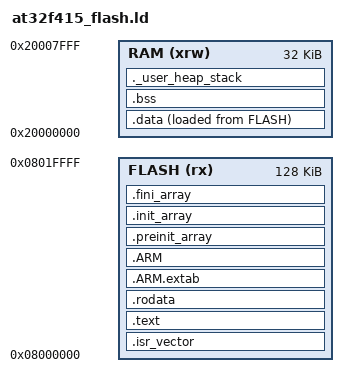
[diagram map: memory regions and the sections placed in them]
/* AT32F415 linker script for split flash layout (kernel/user app/OD). */
OUTPUT_FORMAT("elf32-littlearm", "elf32-bigarm", "elf32-littlearm")
OUTPUT_ARCH(arm)
ENTRY(Reset_Handler)

_Min_Heap_Size = 0x0;
_Min_Stack_Size = 0x300;

MEMORY
{
  FLASH (rx)  : ORIGIN = 0x08000000, LENGTH = 0x20000
  RAM   (xrw) : ORIGIN = 0x20000000, LENGTH = 0x8000
}

_estack = ORIGIN(RAM) + LENGTH(RAM);

SECTIONS
{
  .isr_vector (READONLY) :
  {
    . = ALIGN(4);
    KEEP(*(.isr_vector))
    . = ALIGN(4);
  } > FLASH =0xFF

  .text (READONLY) :
  {
    . = ALIGN(4);
    *(.text)
    *(.text*)
    KEEP(*(.init))
    KEEP(*(.fini))
    . = ALIGN(4);
    _etext = .;
  } > FLASH =0xFF

  .rodata (READONLY) :
  {
    . = ALIGN(4);
    *(.rodata)
    *(.rodata*)
    . = ALIGN(4);
  } > FLASH =0xFF

  .ARM.extab (READONLY) :
  {
    *(.ARM.extab* .gnu.linkonce.armextab.*)
  } > FLASH =0xFF

  .ARM (READONLY) :
  {
    __exidx_start = .;
    *(.ARM.exidx*)
    __exidx_end = .;
  } > FLASH =0xFF

  .preinit_array (READONLY) :
  {
    PROVIDE_HIDDEN(__preinit_array_start = .);
    KEEP(*(.preinit_array*))
    PROVIDE_HIDDEN(__preinit_array_end = .);
  } > FLASH =0xFF

  .init_array (READONLY) :
  {
    PROVIDE_HIDDEN(__init_array_start = .);
    KEEP(*(SORT(.init_array.*)))
    KEEP(*(.init_array*))
    PROVIDE_HIDDEN(__init_array_end = .);
  } > FLASH =0xFF

  .fini_array (READONLY) :
  {
    PROVIDE_HIDDEN(__fini_array_start = .);
    KEEP(*(SORT(.fini_array.*)))
    KEEP(*(.fini_array*))
    PROVIDE_HIDDEN(__fini_array_end = .);
  } > FLASH =0xFF

  _sidata = LOADADDR(.data);

  .data :
  {
    . = ALIGN(4);
    _sdata = .;
    *(.data)
    *(.data*)
    . = ALIGN(4);
    _edata = .;
  } > RAM AT > FLASH

  . = ALIGN(4);
  .bss :
  {
    _sbss = .;
    __bss_start__ = _sbss;
    *(.bss)
    *(.bss*)
    *(COMMON)
    . = ALIGN(4);
    _ebss = .;
    __bss_end__ = _ebss;
  } > RAM

  ._user_heap_stack :
  {
    . = ALIGN(8);
    PROVIDE(end = .);
    PROVIDE(_end = .);
    _bstack = .;
    . = . + _Min_Heap_Size;
    . = . + _Min_Stack_Size;
    . = ALIGN(8);
  } > RAM

  /DISCARD/ :
  {
    libc.a(*)
    libm.a(*)
    libgcc.a(*)
  }

  .ARM.attributes 0 :
  {
    *(.ARM.attributes)
  }
}
